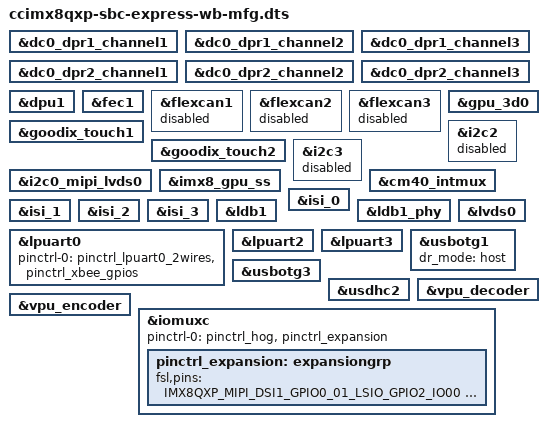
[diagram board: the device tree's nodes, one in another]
/*
 * Copyright 2018, Digi International Inc.
 *
 * Permission to use, copy, modify, and/or distribute this software for any
 * purpose with or without fee is hereby granted, provided that the above
 * copyright notice and this permission notice appear in all copies.
 * THE SOFTWARE IS PROVIDED "AS IS" AND THE AUTHOR DISCLAIMS ALL WARRANTIES
 * WITH REGARD TO THIS SOFTWARE INCLUDING ALL IMPLIED WARRANTIES OF
 * MERCHANTABILITY AND FITNESS. IN NO EVENT SHALL THE AUTHOR BE LIABLE FOR
 * ANY SPECIAL, DIRECT, INDIRECT, OR CONSEQUENTIAL DAMAGES OR ANY DAMAGES
 * WHATSOEVER RESULTING FROM LOSS OF USE, DATA OR PROFITS, WHETHER IN AN
 * ACTION OF CONTRACT, NEGLIGENCE OR OTHER TORTIOUS ACTION, ARISING OUT OF
 * OR IN CONNECTION WITH THE USE OR PERFORMANCE OF THIS SOFTWARE.
 */

/dts-v1/;

/* i.MX8QXP CPU */
#include "../freescale/imx8qxp.dtsi"
/* Digi ConnectCore 8X (WiFi/bluetooth variant) */
#include "ccimx8x-wb.dtsi"
/* Digi ConnectCore 8X SBC Express */
#include "ccimx8x-sbc-express.dtsi"

&dc0_dpr1_channel1 {
	status = "okay";
};

&dc0_dpr1_channel2 {
	status = "okay";
};

&dc0_dpr1_channel3 {
	status = "okay";
};

&dc0_dpr2_channel1 {
	status = "okay";
};

&dc0_dpr2_channel2 {
	status = "okay";
};

&dc0_dpr2_channel3 {
	status = "okay";
};

&dpu1 {
	status = "okay";
};

&fec1 {
	status = "okay";
};

/*
 * CAN1 port conflicts with LPUART0 RTS/CTS lines.
 * Before enabling the port you need to configure
 * lpuart0 node as 2 wires.
 */
&flexcan1 {
	status = "disabled";
};

/* CAN2 */
&flexcan2 {
	status = "disabled";
};


/* CAN3 */
&flexcan3 {
	status = "disabled";
};

/*
 * On the CC8X SBC, an inconsistent reset sequence makes
 * the Goodix display's touch controller respond to two I2C
 * addresses: 0x14 and 0x5D. To make sure the touchscreen
 * works every time, the touch controller's description must
 * be duplicated for both addresses.
 */
&goodix_touch1 {
	status = "okay";
};

&goodix_touch2 {
	status = "okay";
};

&gpu_3d0 {
	status = "okay";
};

/* I2C2 available on Raspberry Pi expansion header */
&i2c2 {
	status = "disabled";
};

/* I2C3 available on Raspberry Pi expansion header */
&i2c3 {
	status = "disabled";
};

/* MIPI-DSI0 I2C available on LVDS connector */
&i2c0_mipi_lvds0 {
	status = "okay";
};

&imx8_gpu_ss {
	status = "okay";
};

&cm40_intmux {
	status = "okay";
};

&isi_0 {
	status = "okay";
};

&isi_1 {
	status = "okay";
};

&isi_2 {
	status = "okay";
};

&isi_3 {
	status = "okay";
};

&ldb1 {
	status = "okay";
};

&ldb1_phy {
	status = "okay";
};

&lvds0 {
	status = "okay";
};

/* LPUART0 on XBee socket */
&lpuart0 {
	/* RTS/CTS lines multiplexed with CAN1 */
	//pinctrl-0 = <&pinctrl_lpuart0_4wires>, <&pinctrl_xbee_gpios>;
	/* Comment the line above and uncomment the next one to use 2-wires */
	pinctrl-0 = <&pinctrl_lpuart0_2wires>, <&pinctrl_xbee_gpios>;
	status = "okay";
};

/* Console */
&lpuart2 {
	status = "okay";
};

/* LPUART3 on expansion header */
&lpuart3 {
	status = "okay";
};

/* USB_OTG1 */
&usbotg1 {
	/*
	 * To configure this USB controller as a device set dr_mode to "otg";
	 * to configure it as a host set to "host" instead.
	 */
	dr_mode = "host";
	status = "okay";
};

/* USB_OTG2 */
&usbotg3 {
	status = "okay";
};

/* Micro SD card */
&usdhc2 {
	status = "okay";
};

&vpu_decoder {
	status = "okay";
};

&vpu_encoder {
	status = "okay";
};

/* IOMUX */
&iomuxc {
	pinctrl-0 = <&pinctrl_hog>, <&pinctrl_expansion>;

	/* Raspberry Pi Expansion Connector */
	pinctrl_expansion: expansiongrp {
		fsl,pins = <
			/* I2C2_SDA (J12 PIN3) */
			IMX8QXP_MIPI_DSI1_GPIO0_01_LSIO_GPIO2_IO00	0x06000020
			/* I2C2_SCL (J12 PIN5) */
			IMX8QXP_MIPI_DSI1_GPIO0_00_LSIO_GPIO1_IO31	0x06000020
			/* GPIO1_IO17 (J12 PIN7) */
			IMX8QXP_FLEXCAN1_RX_LSIO_GPIO1_IO17	0x06000020
			/* GPIO1_IO18 (J12 PIN11) */
			IMX8QXP_FLEXCAN1_TX_LSIO_GPIO1_IO18	0x06000020
			/* GPIO1_IO20 (J12 PIN13) */
			IMX8QXP_FLEXCAN2_TX_LSIO_GPIO1_IO20	0x06000020
			/* GPIO1_IO28 (J12 PIN15) */
			IMX8QXP_MIPI_DSI0_GPIO0_01_LSIO_GPIO1_IO28	0x06000020
			/* SPI3_SDO (J12 PIN19) */
			IMX8QXP_SPI3_SDO_LSIO_GPIO0_IO14		0x06000020
			/* SPI3_SDI (J12 PIN21) */
			IMX8QXP_SPI3_SDI_LSIO_GPIO0_IO15		0x06000020
			/* SPI3_SCK (J12 PIN23) */
			IMX8QXP_SPI3_SCK_LSIO_GPIO0_IO13		0x06000020
			/* GPIO4_21 (J12 PIN29) */
			IMX8QXP_USDHC1_WP_LSIO_GPIO4_IO21		0x06000020
			/* GPIO4_22 (J12 PIN31) */
			IMX8QXP_USDHC1_CD_B_LSIO_GPIO4_IO22	0x06000020
			/* GPIO1_IO29 (J12 PIN16) */
			IMX8QXP_MIPI_DSI1_I2C0_SCL_LSIO_GPIO1_IO29	0x06000020
			/* GPIO1_IO30 (J12 PIN18) */
			IMX8QXP_MIPI_DSI1_I2C0_SDA_LSIO_GPIO1_IO30	0x06000020
			/* GPIO3_IO15 (J12 PIN22) */
			IMX8QXP_QSPI0A_SS1_B_LSIO_GPIO3_IO15	0x06000020
			/* SPI3_CS0 (J12 PIN24) */
			IMX8QXP_SPI3_CS0_LSIO_GPIO0_IO16		0x06000020
			/* GPIO4_IO20 (J12 PIN26) */
			IMX8QXP_USDHC1_VSELECT_LSIO_GPIO4_IO20	0x06000020
			/* GPIO5_03 (J12 PIN32) */
			IMX8QXP_ENET0_RGMII_RXC_LSIO_GPIO5_IO03	0x06000020
			/* GPIO1_19 (J12 PIN40) */
			IMX8QXP_FLEXCAN2_RX_LSIO_GPIO1_IO19		0x06000020

			/* J17 connector */
			/* ADC_IN0 (J17 PIN2) */
			IMX8QXP_ADC_IN0_LSIO_GPIO1_IO10			0x06000020
			/* ADC_IN0 (J17 PIN3) */
			IMX8QXP_ADC_IN1_LSIO_GPIO1_IO09			0x06000020
		>;
	};
};
